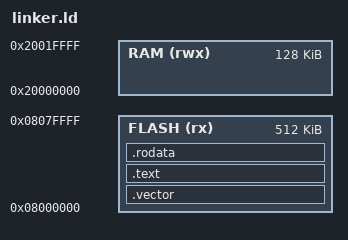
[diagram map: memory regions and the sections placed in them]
ENTRY(Reset_Handler)

MEMORY{
    FLASH (rx) : ORIGIN = 0x08000000, LENGTH = 512K
    RAM (rwx) : ORIGIN = 0x20000000, LENGTH = 128K
}

SECTIONS{
    .vector : { *(.vector) } > FLASH
    .text : { *(.text*) } > FLASH
    .rodata : { *(.rodata*) } > FLASH
}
